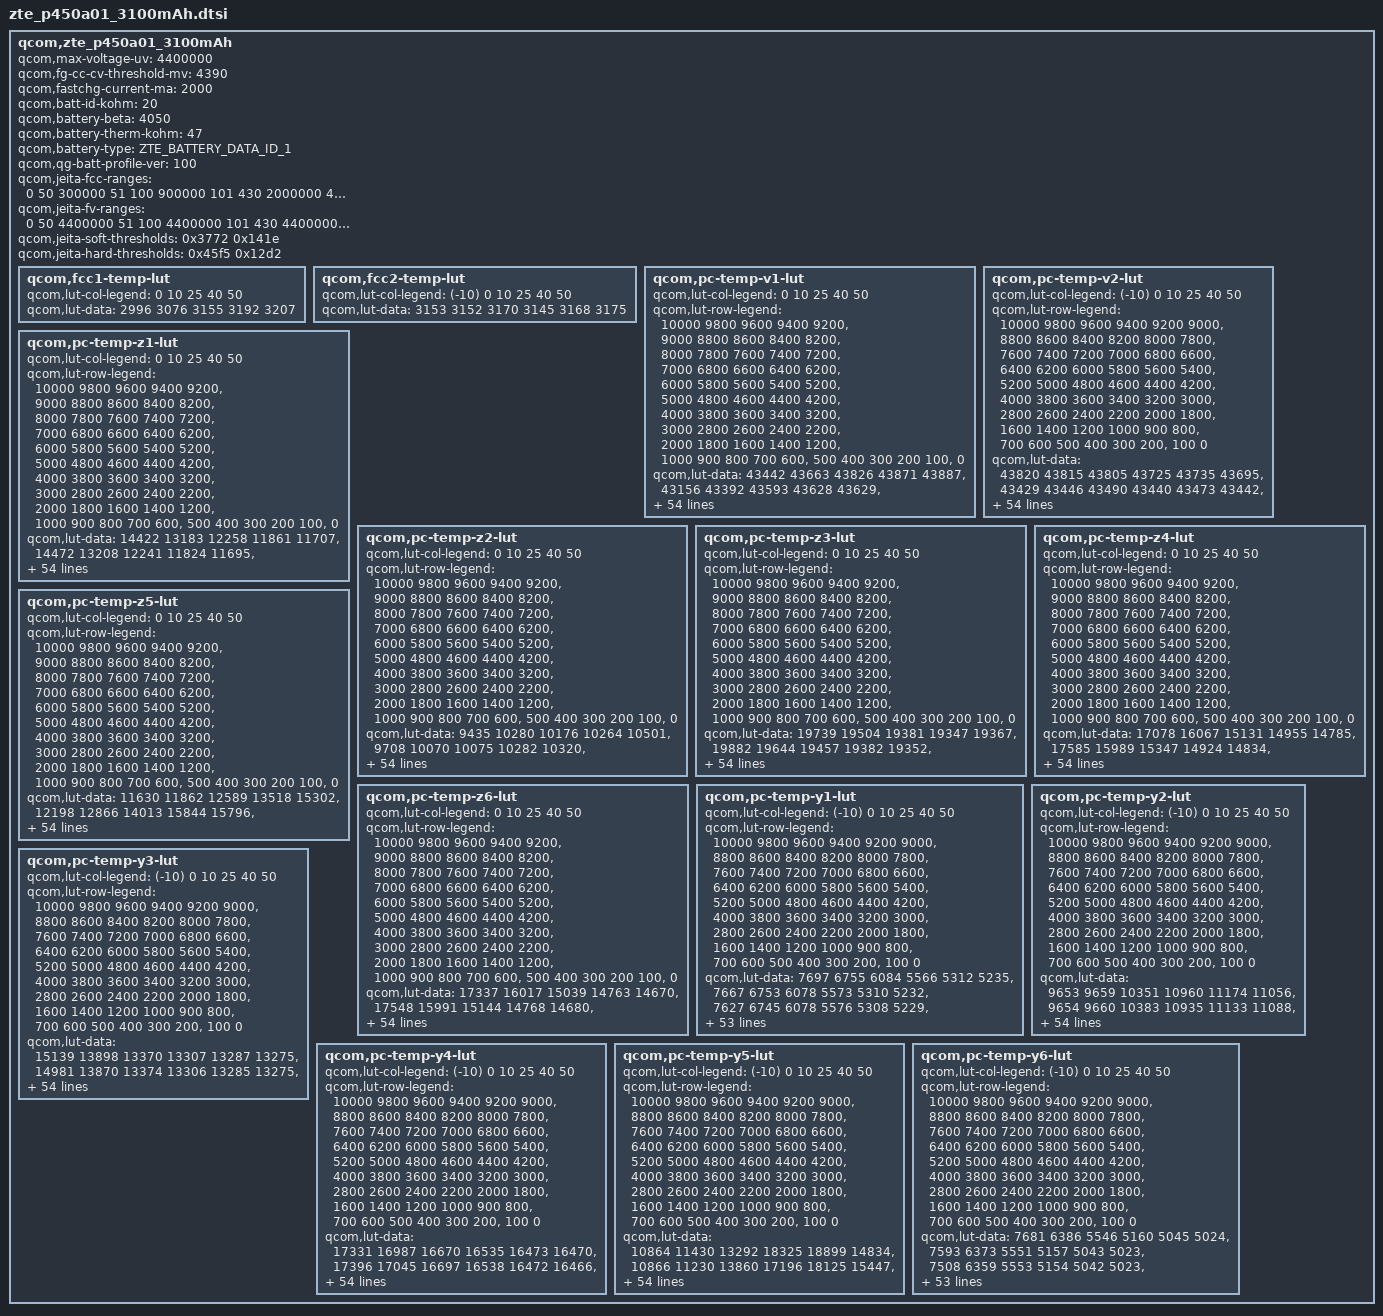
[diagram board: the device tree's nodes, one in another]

qcom,zte_p450a01_3100mAh {
	/* 3612536_ZTE_P450A01cos_3100mAh_averaged_MasterSlave_Aug8th2018 */
	qcom,max-voltage-uv = <4400000>;
	qcom,fg-cc-cv-threshold-mv = <4390>;
	qcom,fastchg-current-ma = <2000>;
	qcom,batt-id-kohm = <20>;
	qcom,battery-beta = <4050>;
	qcom,battery-therm-kohm = <47>;
	qcom,battery-type = "ZTE_BATTERY_DATA_ID_1";
	qcom,qg-batt-profile-ver = <100>;

	qcom,jeita-fcc-ranges = <0   50   300000
				 51 100  900000
				 101 430  2000000
				 431 450  1500000>;
	qcom,jeita-fv-ranges =  <0   50  4400000
				 51 100  4400000
				 101 430  4400000
				 431 450  4400000>;

	/* COOL = 10 DegC, WARM = 43 DegC */
	qcom,jeita-soft-thresholds = <0x3772 0x141e>;
	/* COLD = 0 DegC, HOT = 45 DegC */
	qcom,jeita-hard-thresholds = <0x45f5 0x12d2>;

	qcom,fcc1-temp-lut {
		qcom,lut-col-legend = <0 10 25 40 50>;
		qcom,lut-data = <2996 3076 3155 3192 3207>;
	};

	qcom,fcc2-temp-lut {
		qcom,lut-col-legend = <(-10) 0 10 25 40 50>;
		qcom,lut-data = <3153 3152 3170 3145 3168 3175>;
	};

	qcom,pc-temp-v1-lut {
		qcom,lut-col-legend = <0 10 25 40 50>;
		qcom,lut-row-legend = <10000 9800 9600 9400 9200>,
			<9000 8800 8600 8400 8200>,
			<8000 7800 7600 7400 7200>,
			<7000 6800 6600 6400 6200>,
			<6000 5800 5600 5400 5200>,
			<5000 4800 4600 4400 4200>,
			<4000 3800 3600 3400 3200>,
			<3000 2800 2600 2400 2200>,
			<2000 1800 1600 1400 1200>,
			<1000 900 800 700 600>,
			<500 400 300 200 100>,
			<0>;
		qcom,lut-data = <43442 43663 43826 43871 43887>,
			<43156 43392 43593 43628 43629>,
			<42904 43132 43344 43392 43394>,
			<42668 42887 43100 43154 43161>,
			<42437 42653 42861 42917 42929>,
			<42211 42421 42624 42678 42693>,
			<41992 42192 42388 42440 42458>,
			<41778 41968 42152 42205 42222>,
			<41571 41751 41922 41972 41987>,
			<41379 41540 41697 41742 41756>,
			<41213 41342 41475 41514 41529>,
			<41036 41169 41266 41291 41306>,
			<40798 40989 41079 41075 41087>,
			<40509 40752 40890 40867 40873>,
			<40258 40466 40657 40661 40665>,
			<40055 40226 40399 40454 40464>,
			<39880 40040 40190 40258 40270>,
			<39739 39880 40032 40082 40089>,
			<39622 39748 39885 39915 39917>,
			<39510 39636 39737 39748 39746>,
			<39391 39515 39586 39585 39583>,
			<39274 39380 39389 39405 39408>,
			<39159 39232 39115 39173 39189>,
			<39047 39047 38890 38943 38960>,
			<38939 38828 38764 38790 38793>,
			<38837 38662 38669 38675 38664>,
			<38740 38550 38579 38569 38550>,
			<38650 38464 38497 38467 38446>,
			<38568 38402 38420 38374 38352>,
			<38493 38356 38345 38292 38265>,
			<38425 38315 38277 38219 38187>,
			<38360 38278 38222 38154 38118>,
			<38309 38244 38173 38099 38059>,
			<38269 38214 38129 38048 38003>,
			<38236 38187 38089 38003 37953>,
			<38202 38156 38050 37961 37905>,
			<38168 38123 38010 37912 37847>,
			<38129 38083 37968 37856 37778>,
			<38072 38024 37911 37789 37702>,
			<37998 37933 37821 37704 37619>,
			<37907 37829 37712 37602 37526>,
			<37790 37710 37598 37489 37417>,
			<37656 37579 37467 37358 37287>,
			<37502 37438 37308 37204 37134>,
			<37351 37293 37164 37063 36995>,
			<37241 37181 37072 36976 36911>,
			<37204 37145 37052 36952 36887>,
			<37174 37117 37032 36936 36873>,
			<37143 37092 37012 36920 36855>,
			<37091 37049 36972 36862 36784>,
			<36891 36828 36749 36592 36500>,
			<36453 36392 36329 36155 36055>,
			<35886 35821 35772 35585 35477>,
			<35115 35042 35013 34799 34682>,
			<33901 33818 33847 33581 33443>,
			<30000 30000 30000 30000 30000>;
	};

	qcom,pc-temp-v2-lut {
		qcom,lut-col-legend = <(-10) 0 10 25 40 50>;
		qcom,lut-row-legend = <10000 9800 9600 9400 9200 9000>,
			<8800 8600 8400 8200 8000 7800>,
			<7600 7400 7200 7000 6800 6600>,
			<6400 6200 6000 5800 5600 5400>,
			<5200 5000 4800 4600 4400 4200>,
			<4000 3800 3600 3400 3200 3000>,
			<2800 2600 2400 2200 2000 1800>,
			<1600 1400 1200 1000 900 800>,
			<700 600 500 400 300 200>,
			<100 0>;
		qcom,lut-data = <43820 43815 43805 43725 43735 43695>,
			<43429 43446 43490 43440 43473 43442>,
			<43069 43106 43196 43170 43218 43194>,
			<42741 42798 42924 42913 42972 42952>,
			<42441 42518 42675 42671 42733 42717>,
			<42164 42256 42431 42435 42496 42482>,
			<41900 42010 42183 42203 42262 42247>,
			<41658 41774 41941 41975 42029 42014>,
			<41439 41530 41709 41750 41799 41783>,
			<41237 41278 41486 41527 41571 41555>,
			<41073 41102 41275 41308 41347 41331>,
			<40967 41016 41084 41095 41129 41111>,
			<40850 40927 40892 40886 40915 40895>,
			<40536 40647 40673 40683 40709 40687>,
			<39972 40109 40437 40482 40508 40483>,
			<39604 39754 40200 40278 40313 40288>,
			<39429 39587 39957 40061 40122 40101>,
			<39283 39444 39724 39857 39938 39920>,
			<39108 39262 39522 39691 39767 39750>,
			<38929 39068 39336 39544 39599 39582>,
			<38769 38888 39147 39364 39401 39383>,
			<38620 38720 38952 39120 39157 39145>,
			<38492 38568 38777 38890 38937 38930>,
			<38391 38435 38632 38726 38768 38762>,
			<38306 38317 38503 38590 38624 38616>,
			<38229 38226 38382 38470 38501 38492>,
			<38160 38152 38267 38364 38394 38384>,
			<38096 38090 38167 38268 38296 38285>,
			<38036 38036 38078 38180 38206 38194>,
			<37980 37988 38002 38099 38122 38110>,
			<37924 37944 37942 38024 38048 38035>,
			<37868 37901 37892 37952 37980 37966>,
			<37812 37859 37847 37885 37915 37901>,
			<37753 37816 37804 37824 37854 37839>,
			<37694 37773 37761 37769 37790 37771>,
			<37632 37725 37716 37714 37705 37672>,
			<37566 37673 37668 37662 37605 37551>,
			<37498 37614 37615 37605 37514 37448>,
			<37428 37547 37555 37539 37435 37363>,
			<37359 37472 37487 37465 37357 37282>,
			<37291 37388 37401 37381 37279 37203>,
			<37223 37291 37297 37284 37193 37115>,
			<37155 37177 37178 37174 37081 36999>,
			<37084 37055 37044 37046 36946 36862>,
			<37000 36946 36911 36904 36830 36765>,
			<36899 36858 36836 36866 36801 36743>,
			<36841 36820 36803 36849 36787 36726>,
			<36770 36786 36774 36827 36767 36704>,
			<36673 36736 36723 36793 36727 36651>,
			<36516 36647 36592 36693 36585 36426>,
			<36246 36404 36267 36390 36221 36003>,
			<35843 35955 35754 35905 35695 35448>,
			<35255 35327 35084 35267 35010 34704>,
			<34390 34440 34152 34385 34045 33660>,
			<32945 33106 32812 33010 32655 32293>,
			<29284 28710 27799 30238 27747 27445>;
	};

	qcom,pc-temp-z1-lut {
		qcom,lut-col-legend = <0 10 25 40 50>;
		qcom,lut-row-legend = <10000 9800 9600 9400 9200>,
			<9000 8800 8600 8400 8200>,
			<8000 7800 7600 7400 7200>,
			<7000 6800 6600 6400 6200>,
			<6000 5800 5600 5400 5200>,
			<5000 4800 4600 4400 4200>,
			<4000 3800 3600 3400 3200>,
			<3000 2800 2600 2400 2200>,
			<2000 1800 1600 1400 1200>,
			<1000 900 800 700 600>,
			<500 400 300 200 100>,
			<0>;
		qcom,lut-data = <14422 13183 12258 11861 11707>,
			<14472 13208 12241 11824 11695>,
			<14467 13212 12219 11818 11659>,
			<14442 13196 12206 11801 11662>,
			<14441 13181 12187 11788 11662>,
			<14460 13166 12167 11778 11656>,
			<14462 13148 12151 11771 11650>,
			<14420 13130 12138 11770 11648>,
			<14358 13114 12129 11771 11646>,
			<14325 13099 12132 11771 11645>,
			<14310 13087 12143 11770 11645>,
			<14294 13073 12148 11768 11644>,
			<14252 13056 12145 11768 11644>,
			<14154 13034 12138 11769 11645>,
			<14072 13007 12119 11769 11646>,
			<14005 12999 12088 11767 11648>,
			<13956 13006 12081 11766 11651>,
			<13960 13017 12101 11769 11653>,
			<14001 13033 12121 11774 11655>,
			<14038 13056 12129 11776 11656>,
			<14056 13072 12134 11778 11657>,
			<14070 13082 12141 11779 11658>,
			<14087 13090 12151 11781 11661>,
			<14114 13096 12158 11783 11665>,
			<14136 13111 12163 11788 11669>,
			<14148 13123 12166 11795 11672>,
			<14161 13133 12167 11800 11676>,
			<14165 13142 12168 11804 11682>,
			<14169 13145 12169 11807 11688>,
			<14175 13143 12185 11810 11693>,
			<14175 13143 12206 11815 11696>,
			<14172 13150 12208 11820 11699>,
			<14169 13161 12207 11828 11703>,
			<14165 13175 12206 11836 11707>,
			<14162 13200 12215 11842 11712>,
			<14180 13222 12229 11847 11718>,
			<14243 13246 12245 11853 11724>,
			<14293 13270 12264 11861 11729>,
			<14302 13287 12278 11867 11732>,
			<14302 13301 12289 11871 11735>,
			<14301 13315 12296 11876 11738>,
			<14286 13335 12299 11884 11741>,
			<14290 13349 12301 11894 11748>,
			<14367 13345 12316 11893 11752>,
			<14408 13344 12330 11895 11756>,
			<14399 13338 12339 11899 11759>,
			<14394 13352 12341 11901 11763>,
			<14379 13341 12341 11904 11765>,
			<14321 13347 12353 11908 11770>,
			<14415 13383 12370 11913 11777>,
			<14422 13409 12369 11926 11782>,
			<14444 13439 12395 11935 11791>,
			<14469 13475 12425 11943 11807>,
			<14537 13532 12448 11970 11826>,
			<14537 13532 12448 11970 11826>,
			<14537 13532 12448 11970 11826>;
	};

	qcom,pc-temp-z2-lut {
		qcom,lut-col-legend = <0 10 25 40 50>;
		qcom,lut-row-legend = <10000 9800 9600 9400 9200>,
			<9000 8800 8600 8400 8200>,
			<8000 7800 7600 7400 7200>,
			<7000 6800 6600 6400 6200>,
			<6000 5800 5600 5400 5200>,
			<5000 4800 4600 4400 4200>,
			<4000 3800 3600 3400 3200>,
			<3000 2800 2600 2400 2200>,
			<2000 1800 1600 1400 1200>,
			<1000 900 800 700 600>,
			<500 400 300 200 100>,
			<0>;
		qcom,lut-data = <9435 10280 10176 10264 10501>,
			<9708 10070 10075 10282 10320>,
			<9774 9931 10121 10350 10438>,
			<9809 9904 10164 10352 10380>,
			<9817 9890 10275 10352 10322>,
			<9812 9879 10425 10332 10318>,
			<9806 9867 10445 10303 10325>,
			<9805 9857 10372 10290 10315>,
			<9803 9847 10390 10282 10289>,
			<9803 9839 10437 10274 10277>,
			<9803 9837 10459 10271 10279>,
			<9802 9844 10489 10275 10284>,
			<9794 9851 10613 10282 10298>,
			<9775 9851 10743 10290 10326>,
			<9764 9850 10884 10291 10337>,
			<9759 9851 11082 10291 10335>,
			<9756 9864 11086 10291 10331>,
			<9756 9882 10602 10285 10329>,
			<9758 9904 10216 10272 10333>,
			<9759 9930 10215 10274 10337>,
			<9755 9949 10236 10297 10343>,
			<9747 9964 10239 10317 10353>,
			<9742 9974 10211 10319 10377>,
			<9739 9972 10187 10311 10407>,
			<9738 9965 10179 10318 10418>,
			<9740 9961 10172 10360 10421>,
			<9744 9967 10185 10373 10408>,
			<9749 9978 10219 10336 10331>,
			<9756 9991 10237 10299 10248>,
			<9766 10006 10231 10290 10245>,
			<9779 10015 10221 10287 10275>,
			<9794 10019 10219 10286 10282>,
			<9803 10022 10219 10284 10278>,
			<9712 10025 10220 10288 10280>,
			<9591 10030 10230 10316 10298>,
			<9553 10036 10244 10360 10327>,
			<9444 10052 10255 10392 10356>,
			<9366 10070 10265 10420 10409>,
			<9400 10079 10281 10441 10452>,
			<9461 10085 10312 10462 10479>,
			<9501 10090 10336 10477 10499>,
			<9552 10104 10326 10478 10489>,
			<9568 10112 10308 10473 10452>,
			<9550 9981 10312 10447 10433>,
			<9550 11515 10337 10432 10427>,
			<9543 14979 10352 10444 10449>,
			<9542 15088 10359 10452 10435>,
			<9574 15151 10355 10470 10481>,
			<9560 14500 10409 10480 10496>,
			<9553 15552 10425 10540 10525>,
			<9515 12911 10463 10414 10367>,
			<9435 11692 10424 10367 10276>,
			<9368 13249 10420 10349 10249>,
			<9310 10447 10353 10252 10171>,
			<9310 10447 10353 10252 10171>,
			<9310 10447 10353 10252 10171>;
	};

	qcom,pc-temp-z3-lut {
		qcom,lut-col-legend = <0 10 25 40 50>;
		qcom,lut-row-legend = <10000 9800 9600 9400 9200>,
			<9000 8800 8600 8400 8200>,
			<8000 7800 7600 7400 7200>,
			<7000 6800 6600 6400 6200>,
			<6000 5800 5600 5400 5200>,
			<5000 4800 4600 4400 4200>,
			<4000 3800 3600 3400 3200>,
			<3000 2800 2600 2400 2200>,
			<2000 1800 1600 1400 1200>,
			<1000 900 800 700 600>,
			<500 400 300 200 100>,
			<0>;
		qcom,lut-data = <19739 19504 19381 19347 19367>,
			<19882 19644 19457 19382 19352>,
			<19867 19728 19491 19413 19386>,
			<19840 19747 19510 19425 19391>,
			<19818 19757 19521 19429 19393>,
			<19795 19761 19528 19431 19392>,
			<19784 19761 19531 19431 19391>,
			<19785 19758 19526 19427 19389>,
			<19789 19752 19520 19415 19385>,
			<19793 19739 19514 19406 19381>,
			<19797 19725 19507 19401 19374>,
			<19802 19701 19504 19397 19367>,
			<19819 19681 19505 19392 19364>,
			<19854 19678 19504 19387 19362>,
			<19869 19678 19500 19385 19361>,
			<19854 19675 19496 19384 19360>,
			<19830 19657 19487 19383 19359>,
			<19807 19633 19460 19379 19355>,
			<19782 19609 19440 19373 19350>,
			<19769 19582 19440 19372 19348>,
			<19770 19572 19440 19373 19348>,
			<19774 19579 19443 19374 19347>,
			<19780 19592 19453 19373 19347>,
			<19795 19605 19459 19372 19346>,
			<19808 19623 19452 19373 19353>,
			<19811 19629 19439 19379 19377>,
			<19813 19628 19439 19387 19391>,
			<19811 19626 19448 19404 19391>,
			<19804 19624 19458 19417 19390>,
			<19794 19622 19469 19416 19388>,
			<19786 19619 19478 19412 19383>,
			<19778 19614 19477 19407 19377>,
			<19765 19608 19470 19400 19370>,
			<19671 19601 19464 19394 19364>,
			<19551 19592 19460 19388 19360>,
			<19495 19582 19457 19384 19356>,
			<19373 19571 19453 19381 19356>,
			<19282 19561 19450 19380 19357>,
			<19276 19559 19447 19379 19358>,
			<19273 19563 19445 19377 19358>,
			<19271 19563 19443 19375 19357>,
			<19268 19557 19440 19374 19355>,
			<19268 19542 19437 19372 19353>,
			<19268 19330 19436 19369 19354>,
			<19267 19260 19428 19365 19353>,
			<19267 19257 19413 19356 19343>,
			<19268 19257 19390 19355 19340>,
			<19267 19257 19388 19351 19329>,
			<19267 19257 19393 19344 19325>,
			<19267 19257 19393 19337 19329>,
			<19268 19258 19373 19359 19347>,
			<19271 19258 19368 19367 19358>,
			<19273 19257 19365 19358 19357>,
			<19277 19260 19360 19377 19365>,
			<19277 19260 19360 19377 19365>,
			<19277 19260 19360 19377 19365>;
	};

	qcom,pc-temp-z4-lut {
		qcom,lut-col-legend = <0 10 25 40 50>;
		qcom,lut-row-legend = <10000 9800 9600 9400 9200>,
			<9000 8800 8600 8400 8200>,
			<8000 7800 7600 7400 7200>,
			<7000 6800 6600 6400 6200>,
			<6000 5800 5600 5400 5200>,
			<5000 4800 4600 4400 4200>,
			<4000 3800 3600 3400 3200>,
			<3000 2800 2600 2400 2200>,
			<2000 1800 1600 1400 1200>,
			<1000 900 800 700 600>,
			<500 400 300 200 100>,
			<0>;
		qcom,lut-data = <17078 16067 15131 14955 14785>,
			<17585 15989 15347 14924 14834>,
			<17350 15871 15269 14985 14894>,
			<16946 15692 15104 14922 14864>,
			<16633 15457 14986 14859 14824>,
			<16362 15283 14895 14815 14793>,
			<16128 15161 14840 14781 14765>,
			<15939 15067 14795 14765 14752>,
			<15779 14997 14759 14755 14744>,
			<15638 14942 14743 14747 14738>,
			<15508 14893 14734 14739 14733>,
			<15399 14843 14720 14732 14727>,
			<15316 14810 14689 14724 14720>,
			<15249 14809 14668 14717 14712>,
			<15192 14817 14673 14712 14703>,
			<15140 14820 14690 14706 14696>,
			<15094 14805 14698 14701 14689>,
			<15057 14785 14699 14693 14684>,
			<15024 14776 14697 14686 14680>,
			<14995 14768 14697 14686 14680>,
			<14968 14761 14697 14689 14684>,
			<14943 14748 14715 14696 14691>,
			<14916 14737 14825 14765 14743>,
			<14883 14763 14900 14847 14818>,
			<14857 14848 14896 14850 14822>,
			<14842 14893 14884 14826 14783>,
			<14831 14900 14865 14799 14750>,
			<14825 14903 14830 14764 14732>,
			<14823 14895 14799 14735 14719>,
			<14821 14865 14773 14723 14710>,
			<14817 14836 14753 14716 14703>,
			<14812 14813 14744 14712 14699>,
			<14810 14793 14739 14710 14695>,
			<14896 14774 14735 14708 14693>,
			<15008 14758 14731 14707 14693>,
			<15044 14747 14729 14707 14695>,
			<15151 14739 14725 14708 14698>,
			<15230 14733 14721 14714 14710>,
			<15218 14730 14720 14717 14716>,
			<15200 14727 14723 14716 14713>,
			<15188 14726 14726 14714 14707>,
			<15182 14726 14720 14708 14699>,
			<15174 14727 14708 14697 14690>,
			<15158 14946 14704 14698 14689>,
			<15076 14978 14695 14695 14687>,
			<15047 14946 14675 14673 14667>,
			<15040 14939 14684 14661 14658>,
			<15033 14931 14676 14648 14650>,
			<15026 14924 14659 14641 14637>,
			<15020 14918 14657 14651 14638>,
			<15023 14933 14700 14650 14644>,
			<15054 14953 14714 14647 14641>,
			<15077 14968 14722 14659 14644>,
			<15107 14984 14736 14643 14643>,
			<15107 14984 14736 14643 14643>,
			<15107 14984 14736 14643 14643>;
	};

	qcom,pc-temp-z5-lut {
		qcom,lut-col-legend = <0 10 25 40 50>;
		qcom,lut-row-legend = <10000 9800 9600 9400 9200>,
			<9000 8800 8600 8400 8200>,
			<8000 7800 7600 7400 7200>,
			<7000 6800 6600 6400 6200>,
			<6000 5800 5600 5400 5200>,
			<5000 4800 4600 4400 4200>,
			<4000 3800 3600 3400 3200>,
			<3000 2800 2600 2400 2200>,
			<2000 1800 1600 1400 1200>,
			<1000 900 800 700 600>,
			<500 400 300 200 100>,
			<0>;
		qcom,lut-data = <11630 11862 12589 13518 15302>,
			<12198 12866 14013 15844 15796>,
			<12443 13649 15026 16219 16981>,
			<12624 14159 15873 16900 17141>,
			<12858 14557 16699 17699 17305>,
			<13130 15063 17543 18650 17752>,
			<13400 15747 18516 19398 18356>,
			<13659 16418 19968 19367 18666>,
			<13914 16983 21390 19098 18857>,
			<14144 17556 22130 19015 18933>,
			<14327 18122 22639 19182 18663>,
			<14547 18647 23519 19408 18255>,
			<15071 19266 26672 19506 18312>,
			<15911 20536 28988 19570 18846>,
			<16257 22474 28727 19750 19499>,
			<16108 23117 27640 20399 20415>,
			<15863 22171 26460 21158 21213>,
			<15596 21006 24171 21644 21471>,
			<15178 20060 22762 22149 21567>,
			<14972 18719 24315 23218 21692>,
			<15108 18215 27629 25174 22316>,
			<15421 20561 30144 25972 22806>,
			<15922 24805 32490 23488 20553>,
			<17159 31038 33663 20048 17019>,
			<18637 40053 29046 18257 16592>,
			<20107 43534 21898 16941 17458>,
			<21746 40839 20613 16714 18532>,
			<22853 37016 20812 19211 19863>,
			<23525 34841 21265 22607 21443>,
			<24024 33253 24564 25046 23166>,
			<24433 32102 28796 27201 24964>,
			<24822 31274 30325 28847 25914>,
			<24927 30491 31404 30296 26540>,
			<22234 29433 32391 31230 26916>,
			<18410 28073 34010 31659 27591>,
			<16526 26997 35332 31922 28636>,
			<13136 26073 35238 31739 28618>,
			<10773 25468 34511 30572 27930>,
			<10741 26170 33672 29174 27190>,
			<10749 28500 32072 27451 26184>,
			<10755 29714 30387 25821 25018>,
			<10775 27805 29315 25122 24335>,
			<10791 23778 28573 24574 23838>,
			<10811 13533 28064 22814 23204>,
			<10967 11067 27268 21746 22109>,
			<10999 11076 25807 21663 21118>,
			<10979 11065 19417 22465 21285>,
			<10953 11052 19096 22980 19742>,
			<10949 11025 20832 21807 21473>,
			<10958 11015 21178 18593 21269>,
			<10997 11108 16179 21299 23294>,
			<11034 11043 14926 22650 26312>,
			<10954 10990 14250 19170 23955>,
			<10893 10921 13559 24798 26163>,
			<10893 10921 13559 24798 26163>,
			<10893 10921 13559 24798 26163>;
	};

	qcom,pc-temp-z6-lut {
		qcom,lut-col-legend = <0 10 25 40 50>;
		qcom,lut-row-legend = <10000 9800 9600 9400 9200>,
			<9000 8800 8600 8400 8200>,
			<8000 7800 7600 7400 7200>,
			<7000 6800 6600 6400 6200>,
			<6000 5800 5600 5400 5200>,
			<5000 4800 4600 4400 4200>,
			<4000 3800 3600 3400 3200>,
			<3000 2800 2600 2400 2200>,
			<2000 1800 1600 1400 1200>,
			<1000 900 800 700 600>,
			<500 400 300 200 100>,
			<0>;
		qcom,lut-data = <17337 16017 15039 14763 14670>,
			<17548 15991 15144 14768 14680>,
			<17382 15941 15111 14804 14720>,
			<17100 15847 15035 14780 14709>,
			<16889 15708 14980 14755 14693>,
			<16710 15601 14934 14736 14679>,
			<16560 15524 14901 14720 14665>,
			<16442 15460 14874 14707 14657>,
			<16344 15408 14853 14696 14651>,
			<16256 15363 14842 14687 14646>,
			<16176 15322 14836 14681 14640>,
			<16103 15278 14828 14675 14634>,
			<16033 15244 14814 14670 14629>,
			<15968 15229 14801 14664 14624>,
			<15909 15221 14796 14660 14620>,
			<15850 15211 14793 14656 14616>,
			<15800 15194 14788 14653 14613>,
			<15768 15177 14778 14648 14608>,
			<15743 15166 14770 14642 14604>,
			<15731 15156 14771 14642 14604>,
			<15729 15153 14775 14644 14605>,
			<15728 15156 14788 14649 14609>,
			<15728 15163 14841 14679 14632>,
			<15729 15185 14876 14715 14665>,
			<15731 15232 14872 14717 14670>,
			<15733 15257 14864 14711 14667>,
			<15737 15264 14857 14706 14663>,
			<15738 15267 14849 14701 14657>,
			<15738 15265 14845 14696 14651>,
			<15738 15255 14842 14692 14646>,
			<15738 15245 14841 14688 14641>,
			<15738 15237 14838 14683 14636>,
			<15738 15229 14836 14680 14631>,
			<15733 15222 14835 14677 14627>,
			<15727 15216 14835 14674 14626>,
			<15723 15213 14837 14672 14625>,
			<15720 15213 14838 14673 14626>,
			<15719 15213 14839 14676 14633>,
			<15721 15215 14841 14678 14636>,
			<15727 15225 14847 14678 14635>,
			<15734 15234 14851 14678 14633>,
			<15743 15239 14850 14675 14630>,
			<15751 15242 14848 14671 14626>,
			<15760 15241 14851 14671 14627>,
			<15749 15234 14849 14669 14626>,
			<15742 15230 14838 14657 14613>,
			<15738 15229 14833 14651 14608>,
			<15736 15227 14830 14645 14599>,
			<15738 15227 14831 14638 14592>,
			<15744 15233 14835 14641 14595>,
			<15762 15251 14850 14655 14609>,
			<15788 15272 14860 14661 14616>,
			<15818 15296 14870 14665 14620>,
			<15866 15329 14884 14674 14628>,
			<15866 15329 14884 14674 14628>,
			<15866 15329 14884 14674 14628>;
	};

	qcom,pc-temp-y1-lut {
		qcom,lut-col-legend = <(-10) 0 10 25 40 50>;
		qcom,lut-row-legend = <10000 9800 9600 9400 9200 9000>,
			<8800 8600 8400 8200 8000 7800>,
			<7600 7400 7200 7000 6800 6600>,
			<6400 6200 6000 5800 5600 5400>,
			<5200 5000 4800 4600 4400 4200>,
			<4000 3800 3600 3400 3200 3000>,
			<2800 2600 2400 2200 2000 1800>,
			<1600 1400 1200 1000 900 800>,
			<700 600 500 400 300 200>,
			<100 0>;
		qcom,lut-data = <7697 6755 6084 5566 5312 5235>,
			<7667 6753 6078 5573 5310 5232>,
			<7627 6745 6078 5576 5308 5229>,
			<7587 6734 6079 5576 5306 5226>,
			<7555 6725 6082 5575 5305 5224>,
			<7543 6719 6083 5574 5304 5221>,
			<7544 6716 6085 5570 5302 5219>,
			<7547 6711 6088 5566 5300 5216>,
			<7550 6702 6085 5566 5298 5214>,
			<7557 6687 6075 5568 5296 5211>,
			<7561 6680 6069 5569 5294 5208>,
			<7560 6682 6066 5564 5291 5206>,
			<7558 6686 6065 5559 5289 5205>,
			<7561 6700 6072 5558 5288 5205>,
			<7571 6732 6084 5559 5287 5205>,
			<7572 6746 6091 5561 5287 5205>,
			<7556 6745 6096 5574 5288 5202>,
			<7544 6743 6099 5586 5287 5200>,
			<7553 6745 6100 5585 5287 5200>,
			<7573 6749 6100 5581 5287 5200>,
			<7578 6751 6100 5578 5286 5201>,
			<7554 6747 6103 5575 5287 5202>,
			<7533 6743 6105 5574 5288 5203>,
			<7546 6741 6105 5576 5288 5205>,
			<7574 6737 6105 5579 5288 5209>,
			<7582 6735 6106 5581 5290 5211>,
			<7583 6726 6107 5584 5293 5213>,
			<7583 6719 6109 5586 5296 5214>,
			<7583 6724 6111 5588 5299 5215>,
			<7583 6737 6112 5590 5301 5216>,
			<7579 6744 6112 5590 5303 5217>,
			<7555 6752 6111 5593 5306 5219>,
			<7537 6756 6110 5595 5308 5221>,
			<7536 6747 6112 5597 5313 5225>,
			<7534 6731 6115 5598 5317 5229>,
			<7535 6729 6111 5596 5319 5232>,
			<7552 6737 6103 5591 5319 5236>,
			<7564 6743 6101 5587 5321 5238>,
			<7570 6747 6110 5590 5324 5240>,
			<7580 6751 6117 5594 5328 5241>,
			<7582 6747 6118 5595 5328 5244>,
			<7565 6732 6119 5596 5326 5247>,
			<7560 6740 6123 5594 5328 5247>,
			<7577 6762 6133 5595 5336 5250>,
			<7609 6775 6143 5609 5341 5252>,
			<7633 6803 6141 5620 5343 5257>,
			<7613 6807 6155 5622 5348 5262>,
			<7619 6816 6159 5630 5350 5260>,
			<7644 6818 6161 5624 5349 5258>,
			<7668 6822 6165 5634 5347 5259>,
			<7712 6833 6155 5626 5353 5265>,
			<7720 6822 6171 5646 5365 5274>,
			<7745 6860 6227 5663 5378 5280>,
			<7791 6926 6257 5699 5395 5302>,
			<7791 6926 6257 5699 5395 5302>,
			<7791 6926 6257 5699 5395 5302>;
	};

	qcom,pc-temp-y2-lut {
		qcom,lut-col-legend = <(-10) 0 10 25 40 50>;
		qcom,lut-row-legend = <10000 9800 9600 9400 9200 9000>,
			<8800 8600 8400 8200 8000 7800>,
			<7600 7400 7200 7000 6800 6600>,
			<6400 6200 6000 5800 5600 5400>,
			<5200 5000 4800 4600 4400 4200>,
			<4000 3800 3600 3400 3200 3000>,
			<2800 2600 2400 2200 2000 1800>,
			<1600 1400 1200 1000 900 800>,
			<700 600 500 400 300 200>,
			<100 0>;
		qcom,lut-data = <9653 9659 10351 10960 11174 11056>,
			<9654 9660 10383 10935 11133 11088>,
			<9654 9661 10417 10899 11083 11102>,
			<9655 9663 10448 10861 11031 11102>,
			<9655 9666 10470 10825 10987 11091>,
			<9655 9668 10478 10800 10960 11075>,
			<9655 9672 10470 10777 10939 11019>,
			<9656 9676 10461 10757 10924 10961>,
			<9656 9677 10463 10749 10922 10950>,
			<9656 9677 10473 10744 10920 10947>,
			<9656 9677 10483 10738 10913 10944>,
			<9656 9680 10493 10721 10874 10950>,
			<9656 9682 10510 10705 10836 10960>,
			<9656 9680 10562 10709 10841 10958>,
			<9656 9673 10652 10729 10865 10951>,
			<9656 9670 10679 10747 10885 10942>,
			<9656 9671 10661 10778 10906 10931>,
			<9656 9672 10646 10817 10935 10923>,
			<9656 9671 10647 10851 11002 10941>,
			<9656 9669 10652 10885 11093 10986>,
			<9656 9668 10659 10897 11108 11032>,
			<9655 9668 10676 10893 11056 11086>,
			<9655 9667 10693 10892 11018 11117>,
			<9655 9667 10713 10920 11045 11118>,
			<9655 9666 10730 10972 11083 11114>,
			<9655 9666 10700 10991 11103 11118>,
			<9655 9665 10509 10995 11154 11127>,
			<9655 9664 10374 10998 11188 11138>,
			<9655 9663 10205 11009 11173 11155>,
			<9655 9662 10039 11029 11149 11178>,
			<9655 9661 10005 11034 11159 11239>,
			<9655 9660 9929 11028 11196 11352>,
			<9655 9659 9893 11022 11211 11387>,
			<9654 9658 9921 11016 11208 11315>,
			<9654 9657 9952 11013 11204 11244>,
			<9654 9656 9934 11013 11196 11214>,
			<9654 9656 9864 11011 11198 11192>,
			<9654 9655 9808 11007 11208 11187>,
			<9654 9654 9752 10986 11216 11192>,
			<9654 9654 9711 10948 11220 11195>,
			<9654 9654 9693 10928 11205 11181>,
			<9654 9653 9682 10914 11169 11153>,
			<9654 9653 9676 10895 11166 11137>,
			<9654 9653 9669 10844 11177 11188>,
			<9653 9653 9668 10746 11121 11130>,
			<9653 9653 9662 10733 11038 11059>,
			<9653 9653 9660 10696 11028 11056>,
			<9653 9652 9658 10650 11044 10982>,
			<9653 9652 9657 10662 11007 10977>,
			<9653 9652 9656 10614 10978 10963>,
			<9653 9652 9655 10556 10945 10924>,
			<9652 9652 9653 10486 10876 10863>,
			<9652 9652 9652 10413 10774 10739>,
			<9652 9652 9652 10339 10726 10661>,
			<9652 9652 9652 10339 10726 10661>,
			<9652 9652 9652 10339 10726 10661>;
	};

	qcom,pc-temp-y3-lut {
		qcom,lut-col-legend = <(-10) 0 10 25 40 50>;
		qcom,lut-row-legend = <10000 9800 9600 9400 9200 9000>,
			<8800 8600 8400 8200 8000 7800>,
			<7600 7400 7200 7000 6800 6600>,
			<6400 6200 6000 5800 5600 5400>,
			<5200 5000 4800 4600 4400 4200>,
			<4000 3800 3600 3400 3200 3000>,
			<2800 2600 2400 2200 2000 1800>,
			<1600 1400 1200 1000 900 800>,
			<700 600 500 400 300 200>,
			<100 0>;
		qcom,lut-data = <15139 13898 13370 13307 13287 13275>,
			<14981 13870 13374 13306 13285 13275>,
			<14829 13832 13379 13305 13284 13277>,
			<14689 13792 13384 13305 13283 13278>,
			<14565 13760 13388 13306 13283 13279>,
			<14465 13743 13391 13306 13283 13279>,
			<14393 13738 13393 13310 13283 13279>,
			<14325 13734 13394 13314 13284 13279>,
			<14213 13713 13396 13316 13284 13279>,
			<14055 13655 13398 13317 13283 13279>,
			<13985 13614 13401 13318 13283 13279>,
			<13984 13597 13407 13320 13286 13280>,
			<13984 13581 13413 13323 13290 13280>,
			<13960 13552 13407 13325 13291 13280>,
			<13904 13512 13392 13327 13291 13280>,
			<13881 13495 13383 13328 13291 13280>,
			<13880 13505 13378 13326 13294 13282>,
			<13881 13513 13374 13323 13297 13284>,
			<13883 13495 13367 13322 13297 13287>,
			<13885 13463 13359 13320 13298 13289>,
			<13888 13446 13352 13317 13297 13289>,
			<13893 13436 13346 13311 13291 13285>,
			<13899 13431 13342 13306 13286 13281>,
			<13913 13432 13340 13303 13283 13279>,
			<13936 13436 13339 13301 13281 13278>,
			<13960 13441 13333 13299 13281 13276>,
			<13986 13453 13310 13300 13281 13276>,
			<14015 13468 13293 13300 13281 13275>,
			<14047 13489 13277 13301 13280 13276>,
			<14084 13517 13264 13301 13281 13277>,
			<14124 13548 13263 13300 13281 13277>,
			<14169 13581 13264 13299 13282 13278>,
			<14216 13619 13266 13298 13283 13279>,
			<14266 13665 13277 13298 13283 13278>,
			<14319 13719 13290 13298 13283 13278>,
			<14379 13779 13295 13298 13282 13277>,
			<14448 13848 13299 13299 13280 13276>,
			<14520 13926 13304 13299 13280 13276>,
			<14596 14016 13318 13298 13279 13276>,
			<14677 14117 13335 13297 13280 13276>,
			<14758 14230 13345 13297 13281 13276>,
			<14843 14357 13355 13297 13281 13276>,
			<14938 14482 13382 13299 13280 13277>,
			<15042 14609 13421 13305 13280 13276>,
			<15069 14671 13448 13302 13282 13277>,
			<15165 14794 13530 13309 13282 13280>,
			<15263 14896 13589 13313 13284 13282>,
			<15385 15005 13674 13317 13288 13286>,
			<15513 15105 13770 13326 13293 13288>,
			<15661 15220 13885 13331 13293 13284>,
			<15809 15330 14026 13332 13291 13284>,
			<16019 15472 14266 13340 13291 13288>,
			<16264 15676 14634 13352 13295 13290>,
			<16790 15909 15039 13373 13301 13295>,
			<16790 15909 15039 13373 13301 13295>,
			<16790 15909 15039 13373 13301 13295>;
	};

	qcom,pc-temp-y4-lut {
		qcom,lut-col-legend = <(-10) 0 10 25 40 50>;
		qcom,lut-row-legend = <10000 9800 9600 9400 9200 9000>,
			<8800 8600 8400 8200 8000 7800>,
			<7600 7400 7200 7000 6800 6600>,
			<6400 6200 6000 5800 5600 5400>,
			<5200 5000 4800 4600 4400 4200>,
			<4000 3800 3600 3400 3200 3000>,
			<2800 2600 2400 2200 2000 1800>,
			<1600 1400 1200 1000 900 800>,
			<700 600 500 400 300 200>,
			<100 0>;
		qcom,lut-data = <17331 16987 16670 16535 16473 16470>,
			<17396 17045 16697 16538 16472 16466>,
			<17486 17136 16743 16542 16472 16463>,
			<17578 17233 16793 16546 16473 16462>,
			<17647 17309 16832 16550 16474 16462>,
			<17672 17337 16845 16552 16475 16462>,
			<17661 17329 16842 16552 16476 16464>,
			<17646 17319 16838 16553 16479 16467>,
			<17710 17339 16842 16556 16483 16470>,
			<17960 17437 16863 16563 16489 16473>,
			<18144 17576 16888 16572 16494 16476>,
			<18244 17876 16922 16579 16496 16480>,
			<18302 18143 16966 16588 16499 16485>,
			<18070 17947 17038 16611 16506 16491>,
			<17405 17338 17128 16653 16518 16499>,
			<17139 17100 17144 16686 16531 16509>,
			<17133 17099 17037 16708 16543 16518>,
			<17128 17097 16921 16730 16559 16530>,
			<17087 17072 16873 16766 16594 16555>,
			<17006 17008 16838 16809 16637 16582>,
			<16949 16944 16786 16810 16637 16581>,
			<16909 16879 16709 16683 16575 16540>,
			<16882 16821 16651 16557 16517 16501>,
			<16867 16776 16623 16526 16490 16480>,
			<16856 16740 16605 16510 16472 16466>,
			<16855 16732 16601 16506 16470 16465>,
			<16859 16734 16619 16505 16471 16467>,
			<16864 16737 16634 16504 16473 16470>,
			<16868 16738 16652 16508 16478 16473>,
			<16873 16740 16669 16515 16485 16478>,
			<16876 16743 16671 16520 16494 16484>,
			<16881 16751 16674 16526 16505 16494>,
			<16888 16762 16677 16529 16516 16505>,
			<16894 16773 16675 16528 16528 16518>,
			<16901 16787 16667 16525 16536 16527>,
			<16907 16801 16668 16522 16521 16510>,
			<16914 16816 16684 16519 16485 16474>,
			<16923 16832 16699 16515 16468 16461>,
			<16939 16853 16718 16510 16463 16459>,
			<16961 16872 16737 16507 16461 16459>,
			<16992 16877 16753 16510 16465 16465>,
			<17037 16879 16768 16522 16472 16470>,
			<17089 16872 16781 16537 16476 16470>,
			<17135 16859 16798 16549 16474 16465>,
			<17107 16839 16761 16538 16456 16448>,
			<17098 16857 16797 16559 16476 16467>,
			<17133 16888 16838 16584 16489 16480>,
			<17159 16934 16890 16618 16506 16512>,
			<17193 17002 16947 16663 16542 16548>,
			<17208 17059 17007 16702 16526 16488>,
			<17208 17051 16997 16677 16498 16478>,
			<17212 17012 17009 16696 16506 16498>,
			<17244 17014 17087 16757 16546 16538>,
			<17424 17103 17274 16866 16658 16739>,
			<17424 17103 17274 16866 16658 16739>,
			<17424 17103 17274 16866 16658 16739>;
	};

	qcom,pc-temp-y5-lut {
		qcom,lut-col-legend = <(-10) 0 10 25 40 50>;
		qcom,lut-row-legend = <10000 9800 9600 9400 9200 9000>,
			<8800 8600 8400 8200 8000 7800>,
			<7600 7400 7200 7000 6800 6600>,
			<6400 6200 6000 5800 5600 5400>,
			<5200 5000 4800 4600 4400 4200>,
			<4000 3800 3600 3400 3200 3000>,
			<2800 2600 2400 2200 2000 1800>,
			<1600 1400 1200 1000 900 800>,
			<700 600 500 400 300 200>,
			<100 0>;
		qcom,lut-data = <10864 11430 13292 18325 18899 14834>,
			<10866 11230 13860 17196 18125 15447>,
			<10910 11177 14428 16273 17111 15812>,
			<10988 11236 14921 15586 16093 15994>,
			<11093 11376 15260 15162 15304 16057>,
			<11218 11564 15368 15032 14977 16056>,
			<11422 11973 15256 15463 14903 15633>,
			<11600 12373 15083 16063 14787 14995>,
			<11517 12159 14977 15995 14422 14617>,
			<11158 11257 14892 15387 13753 14331>,
			<11064 10888 14711 14966 13509 14071>,
			<13188 12269 13821 14801 14017 13847>,
			<15530 13794 12996 14672 14534 13614>,
			<14802 13466 13361 14408 14309 13248>,
			<12271 12234 14475 13904 13644 12822>,
			<11334 11819 15277 13657 13429 12727>,
			<11700 12433 15810 13577 13657 12921>,
			<12068 13032 16198 13539 13928 13184>,
			<12096 12972 16457 13995 14084 13459>,
			<12074 12681 16640 15324 14241 13868>,
			<11981 12540 16663 16466 14713 14575>,
			<11496 12398 16582 17544 16259 15998>,
			<11107 12192 16521 18231 17227 16941>,
			<11137 11868 16800 18065 17026 17047>,
			<11210 11475 17209 17479 16587 16931>,
			<11225 11277 16886 17228 16352 16520>,
			<11203 11149 14815 17362 16229 15707>,
			<11180 11082 13092 17576 16161 15350>,
			<11203 11110 11987 17694 15912 15424>,
			<11266 11193 11170 17807 15708 15528>,
			<11298 11278 11134 17727 15872 15678>,
			<11344 11386 11217 17359 16253 15999>,
			<11360 11493 11328 17088 16670 16232>,
			<11376 11629 11541 17185 17232 16308>,
			<11412 11780 11765 17429 17629 16385>,
			<11420 11883 11818 17727 17570 16739>,
			<11370 12006 11737 18142 17299 17214>,
			<11322 12053 11711 18344 17103 17280>,
			<11272 11992 11921 17807 17059 17165>,
			<11229 11900 12104 16747 17051 17034>,
			<11236 11906 12095 15745 16962 16767>,
			<11245 11984 12041 14872 16762 16264>,
			<11331 11921 11930 15092 15763 15776>,
			<11496 11832 11792 15870 15462 15833>,
			<11561 11645 11735 14826 18174 17879>,
			<11695 11522 11772 15294 15145 16038>,
			<11855 11533 11664 14959 15122 15888>,
			<12248 11679 11855 14435 15516 15622>,
			<12703 11742 12101 14571 15624 15516>,
			<13025 12284 12344 14379 16452 16443>,
			<12745 12194 12322 15056 17389 17214>,
			<12323 11707 12308 15436 17310 18947>,
			<11852 11644 12569 15432 17655 18429>,
			<11688 11898 12770 15437 17665 17885>,
			<11688 11898 12770 15437 17665 17885>,
			<11688 11898 12770 15437 17665 17885>;
	};

	qcom,pc-temp-y6-lut {
		qcom,lut-col-legend = <(-10) 0 10 25 40 50>;
		qcom,lut-row-legend = <10000 9800 9600 9400 9200 9000>,
			<8800 8600 8400 8200 8000 7800>,
			<7600 7400 7200 7000 6800 6600>,
			<6400 6200 6000 5800 5600 5400>,
			<5200 5000 4800 4600 4400 4200>,
			<4000 3800 3600 3400 3200 3000>,
			<2800 2600 2400 2200 2000 1800>,
			<1600 1400 1200 1000 900 800>,
			<700 600 500 400 300 200>,
			<100 0>;
		qcom,lut-data = <7681 6386 5546 5160 5045 5024>,
			<7593 6373 5551 5157 5043 5023>,
			<7508 6359 5553 5154 5042 5023>,
			<7428 6343 5553 5153 5041 5022>,
			<7352 6327 5551 5152 5040 5022>,
			<7282 6311 5547 5152 5040 5023>,
			<7212 6293 5536 5152 5041 5023>,
			<7152 6275 5523 5154 5042 5024>,
			<7109 6254 5520 5155 5043 5024>,
			<7073 6231 5518 5156 5044 5025>,
			<7061 6225 5518 5157 5045 5026>,
			<7079 6284 5524 5159 5047 5028>,
			<7097 6350 5533 5163 5050 5029>,
			<7021 6288 5541 5169 5053 5031>,
			<6800 6100 5551 5180 5056 5033>,
			<6712 6026 5551 5189 5060 5035>,
			<6709 6031 5521 5198 5066 5039>,
			<6707 6034 5485 5206 5072 5044>,
			<6696 6022 5465 5213 5083 5053>,
			<6677 5994 5448 5221 5094 5063>,
			<6665 5973 5427 5220 5094 5062>,
			<6658 5955 5400 5179 5072 5047>,
			<6654 5945 5382 5139 5051 5033>,
			<6660 5945 5377 5128 5041 5026>,
			<6675 5946 5373 5123 5035 5020>,
			<6691 5950 5370 5121 5034 5020>,
			<6710 5969 5367 5122 5035 5020>,
			<6731 5994 5366 5123 5036 5020>,
			<6757 6020 5368 5126 5037 5022>,
			<6787 6049 5371 5129 5039 5024>,
			<6817 6081 5377 5132 5043 5027>,
			<6850 6117 5387 5134 5047 5030>,
			<6885 6157 5399 5135 5051 5034>,
			<6923 6203 5412 5136 5055 5037>,
			<6965 6255 5426 5137 5058 5040>,
			<7012 6311 5444 5138 5053 5035>,
			<7064 6374 5466 5138 5042 5024>,
			<7121 6442 5492 5139 5037 5020>,
			<7182 6519 5525 5139 5037 5020>,
			<7248 6603 5564 5139 5036 5020>,
			<7319 6692 5608 5141 5038 5022>,
			<7395 6787 5660 5148 5041 5024>,
			<7481 6881 5724 5160 5042 5025>,
			<7574 6976 5804 5174 5042 5023>,
			<7602 7022 5823 5178 5039 5020>,
			<7680 7121 5938 5197 5046 5028>,
			<7768 7205 6017 5213 5052 5034>,
			<7867 7298 6116 5233 5061 5045>,
			<7979 7395 6219 5260 5074 5058>,
			<8097 7499 6337 5283 5070 5037>,
			<8220 7580 6455 5287 5061 5036>,
			<8391 7681 6655 5314 5066 5045>,
			<8610 7844 6970 5364 5083 5059>,
			<9098 8062 7340 5443 5123 5123>,
			<9098 8062 7340 5443 5123 5123>,
			<9098 8062 7340 5443 5123 5123>;
	};
};
